# PIC32CM2532LS60064 register map
Vendor: Microchip Technology; Series: PIC32CMLS60; File version: 0
CPU: CM23 r0p0, selectable endian, MPU, no FPU, 2 interrupt priority bits
Registers are 32-bit, read-write, reset 0x0 unless marked. A register's access mark holds for its fields unless they carry their own. Offsets are from the block's base; [hi:lo] are bit positions; lines under a group give offsets from that group; {n}, {i} and the like mark numbered series.

## EVSYS — Event System Interface
Base 0x42000000; register names take the prefix EVSYS_
Same registers: EVSYS_SEC 0x42000200 (register names take the prefix EVSYS_SEC_)
0x00 CTRLA 8-bit wo — Control
  [0] SWRST — Software Reset
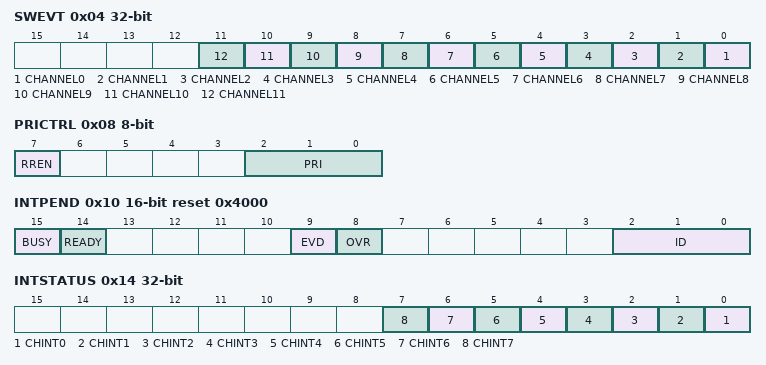
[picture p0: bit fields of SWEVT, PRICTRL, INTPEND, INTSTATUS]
0x04 SWEVT wo — Software Event
  [n] CHANNEL{n} (n=0..11) — Channel {n} Software Selection
0x08 PRICTRL 8-bit — Priority Control
  [7] RREN — Round-Robin Scheduling Enable
  [2:0] PRI — Channel Priority Number
0x10 INTPEND 16-bit reset 0x4000 — Channel Pending Interrupt
  [15] BUSY
  [14] READY
  [9] EVD — Channel Event Detected
  [8] OVR — Channel Overrun
  [2:0] ID — Channel ID
0x14 INTSTATUS ro — Interrupt Status
  [n] CHINT{n} (n=0..7) — Channel {n} Pending Interrupt
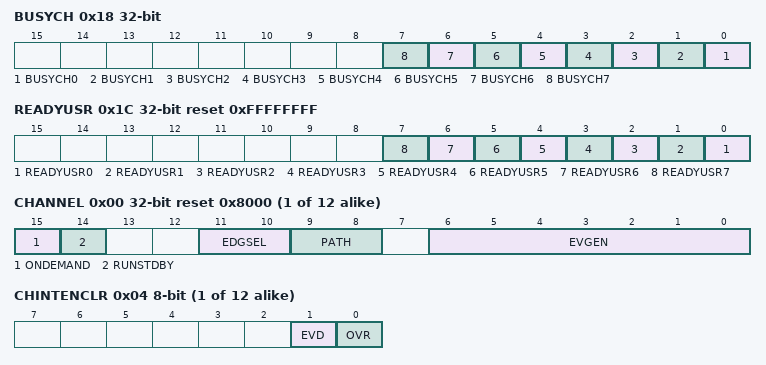
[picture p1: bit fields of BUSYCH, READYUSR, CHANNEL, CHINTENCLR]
0x18 BUSYCH ro — Busy Channels
  [n] BUSYCH{n} (n=0..7) — Busy Channel {n}
0x1C READYUSR ro reset 0xFFFFFFFF — Ready Users
  [n] READYUSR{n} (n=0..7) — Ready User for Channel {n}
{0x20+8i} CHANNEL[{i}] (i=0..11) group
  0x00 CHANNEL reset 0x8000 — Channel n Control
    [15] ONDEMAND — Generic Clock On Demand
    [14] RUNSTDBY — Run in standby
    [11:10] EDGSEL — Edge Detection Selection
      0=NO_EVT_OUTPUT (No event output when using the resynchronized or synchronous path); 1=RISING_EDGE (Event detection only on the rising edge of the signal from the event generator when using the resynchronized or synchronous path); 2=FALLING_EDGE (Event detection only on the falling edge of the signal from the event generator when using the resynchronized or synchronous path); 3=BOTH_EDGES (Event detection on rising and falling edges of the signal from the event generator when using the resynchronized or synchronous path)
    [9:8] PATH — Path Selection
      0=SYNCHRONOUS (Synchronous path); 1=RESYNCHRONIZED (Resynchronized path); 2=ASYNCHRONOUS (Asynchronous path)
    [6:0] EVGEN — Event Generator Selection
  0x04 CHINTENCLR 8-bit — Channel n Interrupt Enable Clear
    [1] EVD — Channel Event Detected Interrupt Disable
    [0] OVR — Channel Overrun Interrupt Disable
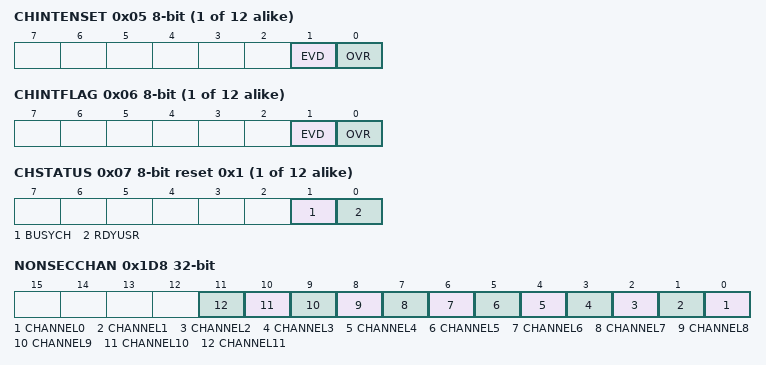
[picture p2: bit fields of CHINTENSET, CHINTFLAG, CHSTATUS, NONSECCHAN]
  0x05 CHINTENSET 8-bit — Channel n Interrupt Enable Set
    [1] EVD — Channel Event Detected Interrupt Enable
    [0] OVR — Channel Overrun Interrupt Enable
  0x06 CHINTFLAG 8-bit — Channel n Interrupt Flag Status and Clear
    [1] EVD — Channel Event Detected
    [0] OVR — Channel Overrun
  0x07 CHSTATUS 8-bit ro reset 0x1 — Channel n Status
    [1] BUSYCH — Busy Channel
    [0] RDYUSR — Ready User
{0x120+i} USER[{i}] (i=0..51) 8-bit — User Multiplexer n
  [3:0] CHANNEL — Channel Event Selection
0x1D4 INTENCLR 8-bit — Interrupt Enable Clear
  [0] NSCHK — Non-Secure Check Interrupt Enable
0x1D5 INTENSET 8-bit — Interrupt Enable Set
  [0] NSCHK — Non-Secure Check Interrupt Enable
0x1D6 INTFLAG 8-bit — Interrupt Flag Status and Clear
  [0] NSCHK — Non-Secure Check
0x1D8 NONSECCHAN — Channels Security Attribution
  [n] CHANNEL{n} (n=0..11) — Non-Secure for Channel {n}
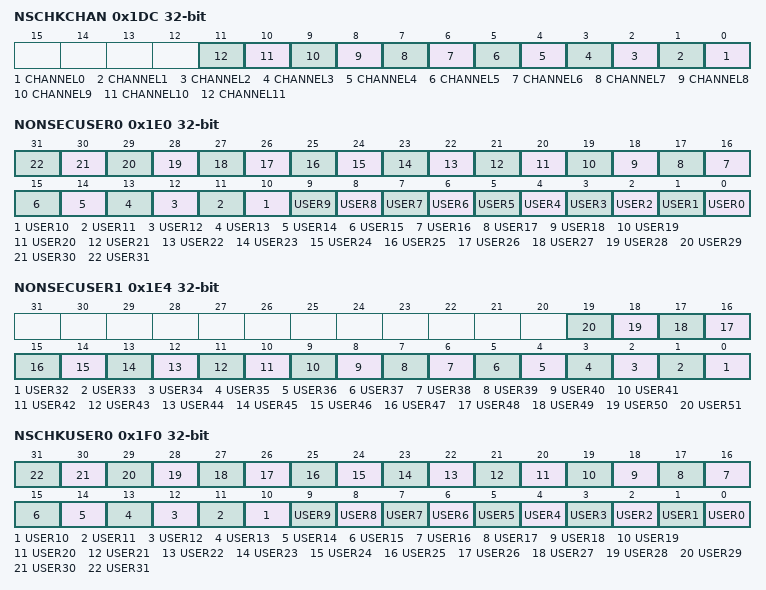
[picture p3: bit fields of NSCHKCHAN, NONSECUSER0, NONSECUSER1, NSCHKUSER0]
0x1DC NSCHKCHAN — Non-Secure Channels Check
  [n] CHANNEL{n} (n=0..11) — Channel {n} to be checked as non-secured
0x1E0 NONSECUSER0 — Users Security Attribution
  [n] USER{n} (n=0..31) — Non-Secure for User {n}
0x1E4 NONSECUSER1 — Users Security Attribution
  [n-32] USER{n} (n=32..51) — Non-Secure for User {n}
0x1F0 NSCHKUSER0 — Non-Secure Users Check
  [n] USER{n} (n=0..31) — User {n} to be checked as non-secured
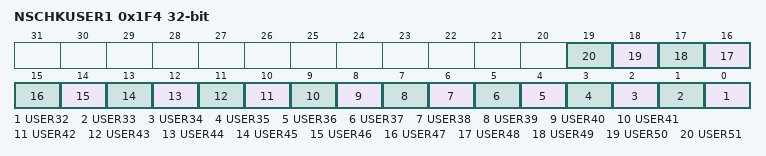
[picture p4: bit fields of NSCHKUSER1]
0x1F4 NSCHKUSER1 — Non-Secure Users Check
  [n-32] USER{n} (n=32..51) — User {n} to be checked as non-secured

## FPB — Flash Patch and Breakpoint
Base 0xE0002000; register names take the prefix FPB_
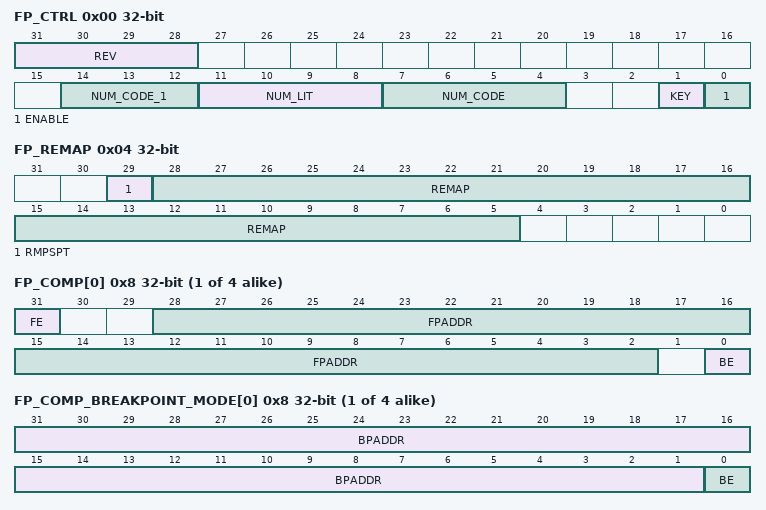
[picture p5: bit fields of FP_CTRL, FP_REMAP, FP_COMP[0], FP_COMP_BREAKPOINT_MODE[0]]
0x00 FP_CTRL — Flash Patch Control Register
  [31:28] REV — Revision
  [14:12] NUM_CODE_1 — Number of implemented code comparators bits [6:4]
  [11:8] NUM_LIT — Number of literal comparators
  [7:4] NUM_CODE — Number of implemented code comparators bits [3:0]
  [1] KEY — FP_CTRL write-enable key
  [0] ENABLE — Flash Patch global enable
0x04 FP_REMAP ro — Flash Patch Remap Register
  [29] RMPSPT — Remap supported
  [28:5] REMAP — Remap address
{0x8+4i} FP_COMP[{i}] (i=0..3) — Flash Patch Comparator Register n
  [31] FE — Flash Patch enable
  [28:2] FPADDR — Flash Patch address
  [0] BE — Breakpoint enable
{0x8+4i} FP_COMP_BREAKPOINT_MODE[{i}] (i=0..3) (alternate view of FP_COMP[{i}]) — Flash Patch Comparator Register n
  [31:1] BPADDR — Breakpoint address
  [0] BE — Breakpoint enable
0xFB0 FP_LAR wo — FPB Software Lock Access Register
  [31:0] KEY — Lock access control
    0xC5ACCE55=UNLOCK (Unlock key value)
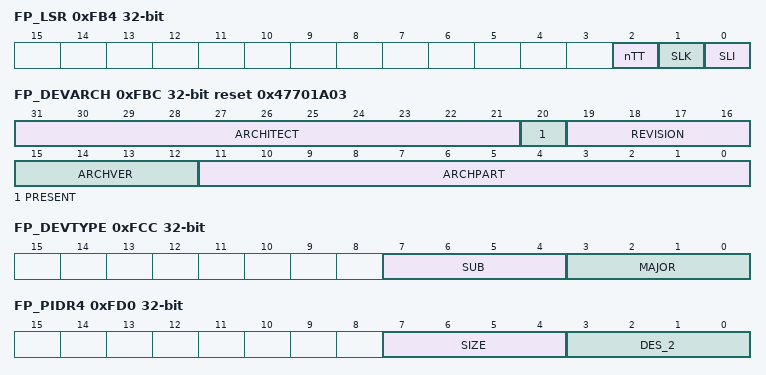
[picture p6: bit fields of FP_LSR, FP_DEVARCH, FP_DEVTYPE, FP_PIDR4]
0xFB4 FP_LSR ro — FPB Software Lock Status Register
  [2] nTT — Not thirty-two bit
  [1] SLK — Software Lock status
  [0] SLI — Software Lock implemented
0xFBC FP_DEVARCH ro reset 0x47701A03 — FPB Device Architecture Register
  [31:21] ARCHITECT
  [20] PRESENT — DEVARCH Present
  [19:16] REVISION
  [15:12] ARCHVER — Architecture Version
  [11:0] ARCHPART — Architecture Part
0xFCC FP_DEVTYPE ro — FPB Device Type Register
  [7:4] SUB — Sub-type
  [3:0] MAJOR — Major type
0xFD0 FP_PIDR4 ro — FP Peripheral Identification Register 4
  [7:4] SIZE — 4KB count
  [3:0] DES_2 — JEP106 continuation code
{0xFC0+4i} FP_PIDR{i} ro (i=5..7) — FP Peripheral Identification Register {i}
0xFE0 FP_PIDR0 ro — FP Peripheral Identification Register 0
  [7:0] PART_0 — Part number bits[7:0]
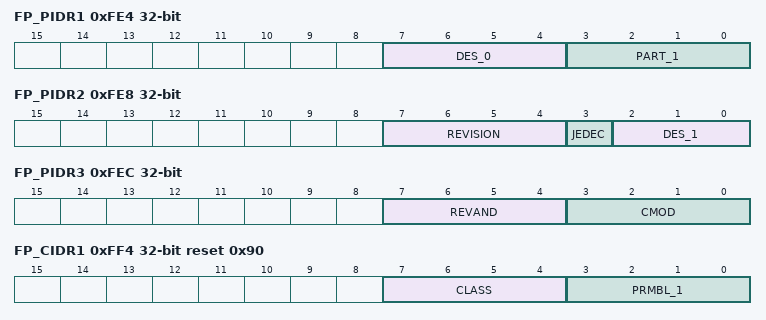
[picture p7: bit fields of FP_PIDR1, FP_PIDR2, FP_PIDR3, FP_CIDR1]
0xFE4 FP_PIDR1 ro — FP Peripheral Identification Register 1
  [7:4] DES_0 — JEP106 identification code bits [3:0]
  [3:0] PART_1 — Part number bits[11:8]
0xFE8 FP_PIDR2 ro — FP Peripheral Identification Register 2
  [7:4] REVISION — Component revision
  [3] JEDEC — JEDEC assignee value is used
  [2:0] DES_1 — JEP106 identification code bits[6:4]
0xFEC FP_PIDR3 ro — FP Peripheral Identification Register 3
  [7:4] REVAND
  [3:0] CMOD — Customer Modified
0xFF0 FP_CIDR0 ro reset 0xD — FP Component Identification Register 0
  [7:0] PRMBL_0 — CoreSight component identification preamble
0xFF4 FP_CIDR1 ro reset 0x90 — FP Component Identification Register 1
  [7:4] CLASS — CoreSight component class
  [3:0] PRMBL_1 — CoreSight component identification preamble
0xFF8 FP_CIDR2 ro reset 0x5 — FP Component Identification Register 2
  [7:0] PRMBL_2 — CoreSight component identification preamble
0xFFC FP_CIDR3 ro reset 0xB1 — FP Component Identification Register 3
  [7:0] PRMBL_3 — CoreSight component identification preamble
